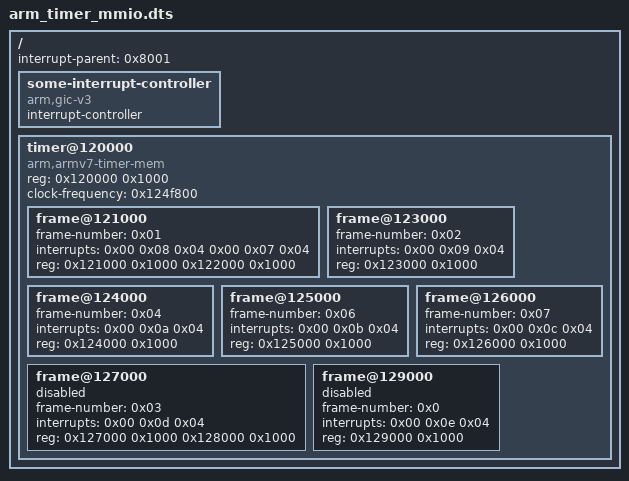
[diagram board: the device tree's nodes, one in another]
// Copyright 2025 The Fuchsia Authors. All rights reserved.
// Use of this source code is governed by a BSD-style license that can be
// found in the LICENSE file.

/dts-v1/;

/ {
    interrupt-parent = <0x8001>;
    #size-cells = <0x01>;
    #address-cells = <0x01>;
    some-interrupt-controller {
        #address-cells = <0x02>;
        #size-cells = <0x02>;
        #interrupt-cells = <0x03>;
        compatible = "arm,gic-v3";
        phandle = <0x8001>;
        interrupt-controller;
    };
    timer@120000 {
        #address-cells = <0x01>;
        #size-cells = <0x01>;
        compatible = "arm,armv7-timer-mem";
        reg = <0x120000 0x1000>;
        clock-frequency = <0x124f800>;
        phandle = <0x192>;

        frame@121000 {
            frame-number = <0x01>;
            interrupts = <0x00 0x08 0x04 0x00 0x07 0x04>;
            reg = <0x121000 0x1000 0x122000 0x1000>;
        };

        frame@123000 {
            frame-number = <0x02>;
            interrupts = <0x00 0x09 0x04>;
            reg = <0x123000 0x1000>;
        };

        frame@124000 {
            frame-number = <0x04>;
            interrupts = <0x00 0x0a 0x04>;
            reg = <0x124000 0x1000>;
        };

        frame@125000 {
            frame-number = <0x06>;
            interrupts = <0x00 0x0b 0x04>;
            reg = <0x125000 0x1000>;
        };

        frame@126000 {
            frame-number = <0x07>;
            interrupts = <0x00 0x0c 0x04>;
            reg = <0x126000 0x1000>;
        };

        frame@127000 {
            frame-number = <0x03>;
            interrupts = <0x00 0x0d 0x04>;
            reg = <0x127000 0x1000 0x128000 0x1000>;
            status = "disabled";
        };

        frame@129000 {
            frame-number = <0x0>;
            interrupts = <0x00 0x0e 0x04>;
            reg = <0x129000 0x1000>;
            status = "disabled";
        };
    };
};
